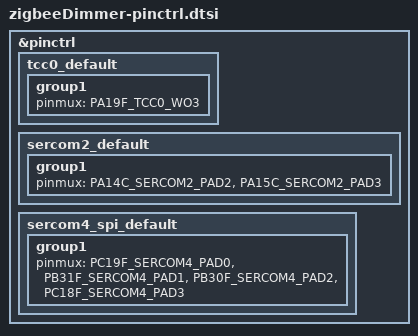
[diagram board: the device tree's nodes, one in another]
/*
 * Copyright (c) 2021 Argentum Systems Ltd.
 *
 * SPDX-License-Identifier: Apache-2.0
 */

#include <dt-bindings/pinctrl/samr30e-pinctrl.h>

&pinctrl {
	tcc0_default: tcc0_default {
		group1 {
			pinmux = <PA19F_TCC0_WO3>;
		};
	};

	sercom2_default: sercom2_default {
		group1 {
			pinmux = <PA14C_SERCOM2_PAD2>,
				 <PA15C_SERCOM2_PAD3>;
		};
	};

	sercom4_spi_default: sercom4_spi_default {
		group1 {
			pinmux = <PC19F_SERCOM4_PAD0>,
				 <PB31F_SERCOM4_PAD1>,
				 <PB30F_SERCOM4_PAD2>,
				 <PC18F_SERCOM4_PAD3>;
		};
	};
};
